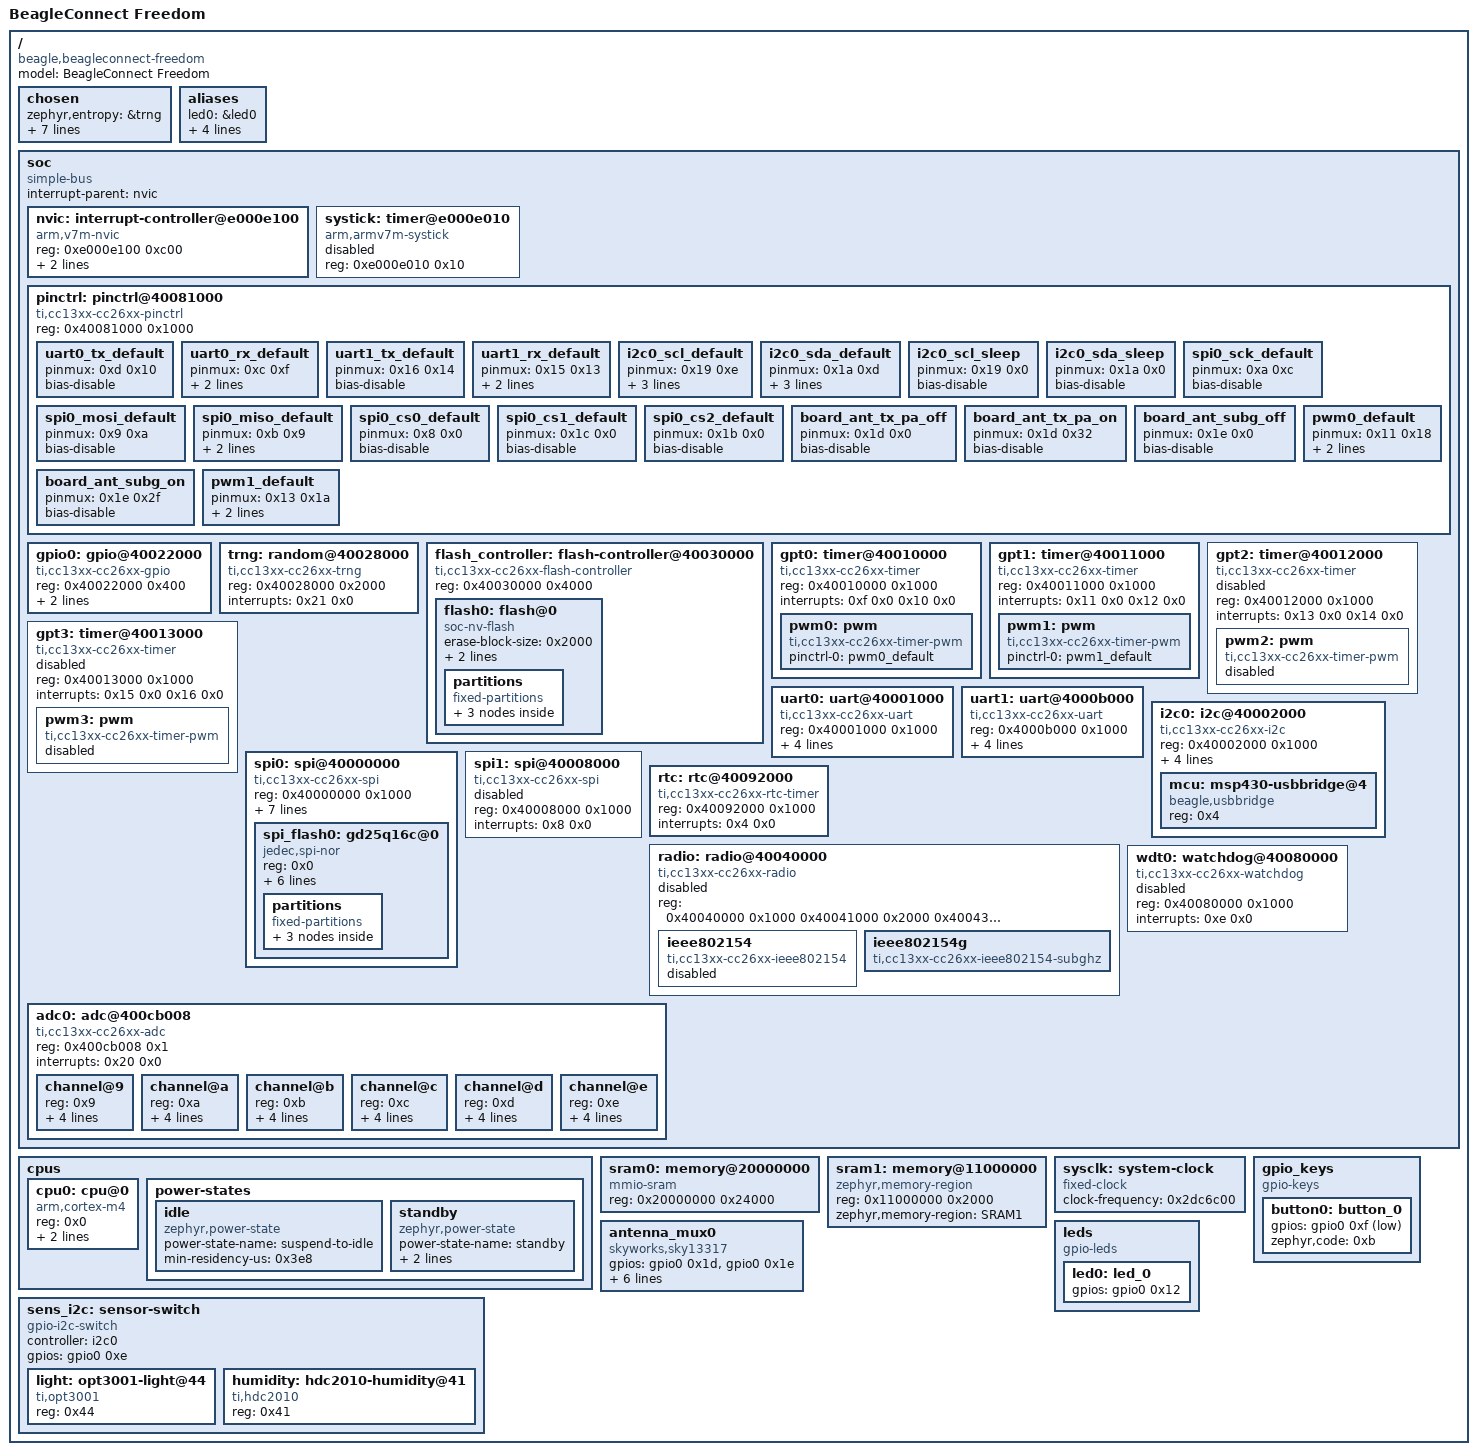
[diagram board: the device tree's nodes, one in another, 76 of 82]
/dts-v1/;

/ {
	#address-cells = < 0x1 >;
	#size-cells = < 0x1 >;
	model = "BeagleConnect Freedom";
	compatible = "beagle,beagleconnect-freedom";
	chosen {
		zephyr,entropy = &trng;
		zephyr,flash-controller = &flash_controller;
		zephyr,sram = &sram0;
		zephyr,console = &uart0;
		zephyr,shell-uart = &uart0;
		zephyr,flash = &flash0;
		zephyr,ieee802154 = &ieee802154g;
		zephyr,code-partition = &slot0_partition;
	};
	aliases {
		led0 = &led0;
		sw0 = &button0;
		mcuboot-button0 = &button0;
		sensor0 = &light;
		sensor1 = &humidity;
	};
	soc {
		#address-cells = < 0x1 >;
		#size-cells = < 0x1 >;
		compatible = "simple-bus";
		interrupt-parent = < &nvic >;
		ranges;
		nvic: interrupt-controller@e000e100 {
			#address-cells = < 0x1 >;
			compatible = "arm,v7m-nvic";
			reg = < 0xe000e100 0xc00 >;
			interrupt-controller;
			#interrupt-cells = < 0x2 >;
			arm,num-irq-priority-bits = < 0x3 >;
			phandle = < 0x1 >;
		};
		systick: timer@e000e010 {
			compatible = "arm,armv7m-systick";
			reg = < 0xe000e010 0x10 >;
			status = "disabled";
		};
		pinctrl: pinctrl@40081000 {
			compatible = "ti,cc13xx-cc26xx-pinctrl";
			reg = < 0x40081000 0x1000 >;
			uart0_tx_default: uart0_tx_default {
				pinmux = < 0xd 0x10 >;
				bias-disable;
				phandle = < 0x6 >;
			};
			uart0_rx_default: uart0_rx_default {
				pinmux = < 0xc 0xf >;
				bias-disable;
				input-enable;
				phandle = < 0x5 >;
			};
			uart1_tx_default: uart1_tx_default {
				pinmux = < 0x16 0x14 >;
				bias-disable;
				phandle = < 0x8 >;
			};
			uart1_rx_default: uart1_rx_default {
				pinmux = < 0x15 0x13 >;
				bias-disable;
				input-enable;
				phandle = < 0x7 >;
			};
			i2c0_scl_default: i2c0_scl_default {
				pinmux = < 0x19 0xe >;
				bias-pull-up;
				drive-open-drain;
				input-enable;
				phandle = < 0x9 >;
			};
			i2c0_sda_default: i2c0_sda_default {
				pinmux = < 0x1a 0xd >;
				bias-pull-up;
				drive-open-drain;
				input-enable;
				phandle = < 0xa >;
			};
			i2c0_scl_sleep: i2c0_scl_sleep {
				pinmux = < 0x19 0x0 >;
				bias-disable;
				phandle = < 0xb >;
			};
			i2c0_sda_sleep: i2c0_sda_sleep {
				pinmux = < 0x1a 0x0 >;
				bias-disable;
				phandle = < 0xc >;
			};
			spi0_sck_default: spi0_sck_default {
				pinmux = < 0xa 0xc >;
				bias-disable;
				phandle = < 0xd >;
			};
			spi0_mosi_default: spi0_mosi_default {
				pinmux = < 0x9 0xa >;
				bias-disable;
				phandle = < 0xe >;
			};
			spi0_miso_default: spi0_miso_default {
				pinmux = < 0xb 0x9 >;
				bias-disable;
				input-enable;
				phandle = < 0xf >;
			};
			spi0_cs0_default: spi0_cs0_default {
				pinmux = < 0x8 0x0 >;
				bias-disable;
				phandle = < 0x10 >;
			};
			spi0_cs1_default: spi0_cs1_default {
				pinmux = < 0x1c 0x0 >;
				bias-disable;
				phandle = < 0x11 >;
			};
			spi0_cs2_default: spi0_cs2_default {
				pinmux = < 0x1b 0x0 >;
				bias-disable;
				phandle = < 0x12 >;
			};
			board_ant_tx_pa_off: board_ant_tx_pa_off {
				pinmux = < 0x1d 0x0 >;
				bias-disable;
				phandle = < 0x16 >;
			};
			board_ant_tx_pa_on: board_ant_tx_pa_on {
				pinmux = < 0x1d 0x32 >;
				bias-disable;
				phandle = < 0x19 >;
			};
			board_ant_subg_off: board_ant_subg_off {
				pinmux = < 0x1e 0x0 >;
				bias-disable;
				phandle = < 0x17 >;
			};
			board_ant_subg_on: board_ant_subg_on {
				pinmux = < 0x1e 0x2f >;
				bias-disable;
				phandle = < 0x18 >;
			};
			pwm0_default: pwm0_default {
				pinmux = < 0x11 0x18 >;
				bias-disable;
				drive-strength = < 0x2 >;
				phandle = < 0x2 >;
			};
			pwm1_default: pwm1_default {
				pinmux = < 0x13 0x1a >;
				bias-disable;
				drive-strength = < 0x2 >;
				phandle = < 0x3 >;
			};
		};
		gpio0: gpio@40022000 {
			compatible = "ti,cc13xx-cc26xx-gpio";
			reg = < 0x40022000 0x400 >;
			interrupts = < 0x0 0x0 >;
			status = "okay";
			gpio-controller;
			#gpio-cells = < 0x2 >;
			phandle = < 0x13 >;
		};
		trng: random@40028000 {
			compatible = "ti,cc13xx-cc26xx-trng";
			reg = < 0x40028000 0x2000 >;
			interrupts = < 0x21 0x0 >;
			status = "okay";
		};
		flash_controller: flash-controller@40030000 {
			compatible = "ti,cc13xx-cc26xx-flash-controller";
			reg = < 0x40030000 0x4000 >;
			#address-cells = < 0x1 >;
			#size-cells = < 0x1 >;
			flash0: flash@0 {
				compatible = "soc-nv-flash";
				erase-block-size = < 0x2000 >;
				write-block-size = < 0x1 >;
				reg = < 0x0 0xb0000 >;
				partitions {
					compatible = "fixed-partitions";
					#address-cells = < 0x1 >;
					#size-cells = < 0x1 >;
					ti_ccfg_partition: partition@affa8 {
						compatible = "zephyr,memory-region";
						reg = < 0xaffa8 0x58 >;
						zephyr,memory-region = "FLASH_CCFG";
					};
					boot_partition: partition@0 {
						label = "mcuboot";
						reg = < 0x0 0x20000 >;
					};
					slot0_partition: partition@20000 {
						label = "image-0";
						reg = < 0x20000 0x8e000 >;
					};
				};
			};
		};
		gpt0: timer@40010000 {
			compatible = "ti,cc13xx-cc26xx-timer";
			reg = < 0x40010000 0x1000 >;
			interrupts = < 0xf 0x0 0x10 0x0 >;
			interrupt-names = "gpt0a", "gpt0b";
			status = "okay";
			pwm0: pwm {
				compatible = "ti,cc13xx-cc26xx-timer-pwm";
				#pwm-cells = < 0x3 >;
				status = "okay";
				pinctrl-0 = < &pwm0_default >;
				pinctrl-names = "default";
			};
		};
		gpt1: timer@40011000 {
			compatible = "ti,cc13xx-cc26xx-timer";
			reg = < 0x40011000 0x1000 >;
			interrupts = < 0x11 0x0 0x12 0x0 >;
			interrupt-names = "gpt1a", "gpt1b";
			status = "okay";
			pwm1: pwm {
				compatible = "ti,cc13xx-cc26xx-timer-pwm";
				#pwm-cells = < 0x3 >;
				status = "okay";
				pinctrl-0 = < &pwm1_default >;
				pinctrl-names = "default";
			};
		};
		gpt2: timer@40012000 {
			compatible = "ti,cc13xx-cc26xx-timer";
			reg = < 0x40012000 0x1000 >;
			interrupts = < 0x13 0x0 0x14 0x0 >;
			interrupt-names = "gpt2a", "gpt2b";
			status = "disabled";
			pwm2: pwm {
				compatible = "ti,cc13xx-cc26xx-timer-pwm";
				#pwm-cells = < 0x3 >;
				status = "disabled";
			};
		};
		gpt3: timer@40013000 {
			compatible = "ti,cc13xx-cc26xx-timer";
			reg = < 0x40013000 0x1000 >;
			interrupts = < 0x15 0x0 0x16 0x0 >;
			interrupt-names = "gpt3a", "gpt3b";
			status = "disabled";
			pwm3: pwm {
				compatible = "ti,cc13xx-cc26xx-timer-pwm";
				#pwm-cells = < 0x3 >;
				status = "disabled";
			};
		};
		uart0: uart@40001000 {
			compatible = "ti,cc13xx-cc26xx-uart";
			reg = < 0x40001000 0x1000 >;
			interrupts = < 0x5 0x0 >;
			clocks = < &sysclk >;
			status = "okay";
			current-speed = < 0x1c200 >;
			pinctrl-0 = < &uart0_rx_default &uart0_tx_default >;
			pinctrl-names = "default";
		};
		uart1: uart@4000b000 {
			compatible = "ti,cc13xx-cc26xx-uart";
			reg = < 0x4000b000 0x1000 >;
			interrupts = < 0x24 0x0 >;
			clocks = < &sysclk >;
			status = "okay";
			current-speed = < 0x1c200 >;
			pinctrl-0 = < &uart1_rx_default &uart1_tx_default >;
			pinctrl-names = "default";
		};
		i2c0: i2c@40002000 {
			compatible = "ti,cc13xx-cc26xx-i2c";
			#address-cells = < 0x1 >;
			#size-cells = < 0x0 >;
			reg = < 0x40002000 0x1000 >;
			interrupts = < 0x1 0x0 >;
			clock-frequency = < 0x61a80 >;
			status = "okay";
			pinctrl-0 = < &i2c0_scl_default &i2c0_sda_default >;
			pinctrl-1 = < &i2c0_scl_sleep &i2c0_sda_sleep >;
			pinctrl-names = "default", "sleep";
			phandle = < 0x1a >;
			mcu: msp430-usbbridge@4 {
				compatible = "beagle,usbbridge";
				reg = < 0x4 >;
			};
		};
		spi0: spi@40000000 {
			compatible = "ti,cc13xx-cc26xx-spi";
			#address-cells = < 0x1 >;
			#size-cells = < 0x0 >;
			reg = < 0x40000000 0x1000 >;
			interrupts = < 0x7 0x0 >;
			status = "okay";
			pinctrl-0 = < &spi0_sck_default &spi0_mosi_default &spi0_miso_default &spi0_cs0_default &spi0_cs1_default &spi0_cs2_default >;
			pinctrl-names = "default";
			cs-gpios = < &gpio0 0x8 0x1 >, < &gpio0 0x1c 0x1 >, < &gpio0 0x1b 0x1 >;
			spi_flash0: gd25q16c@0 {
				compatible = "jedec,spi-nor";
				reg = < 0x0 >;
				spi-max-frequency = < 0x1e8480 >;
				size = < 0x200000 >;
				has-dpd;
				t-enter-dpd = < 0x4e20 >;
				t-exit-dpd = < 0x186a0 >;
				jedec-id = [ C8 40 15 ];
				partitions {
					compatible = "fixed-partitions";
					#address-cells = < 0x1 >;
					#size-cells = < 0x1 >;
					slot1_partition: partition@0 {
						label = "image-1";
						reg = < 0x0 0x8e000 >;
					};
					scratch_partition: partition@8e000 {
						label = "image-scratch";
						reg = < 0x8e000 0x20000 >;
					};
					storage_partition: partition@ae000 {
						label = "storage";
						reg = < 0xae000 0x100000 >;
					};
				};
			};
		};
		spi1: spi@40008000 {
			compatible = "ti,cc13xx-cc26xx-spi";
			#address-cells = < 0x1 >;
			#size-cells = < 0x0 >;
			reg = < 0x40008000 0x1000 >;
			interrupts = < 0x8 0x0 >;
			status = "disabled";
		};
		rtc: rtc@40092000 {
			compatible = "ti,cc13xx-cc26xx-rtc-timer";
			reg = < 0x40092000 0x1000 >;
			interrupts = < 0x4 0x0 >;
			status = "okay";
		};
		radio: radio@40040000 {
			compatible = "ti,cc13xx-cc26xx-radio";
			status = "disabled";
			reg = < 0x40040000 0x1000 0x40041000 0x2000 0x40043000 0x1000 0x40044000 0x1000 >;
			reg-names = "RFC_PWR", "RFC_DBELL", "RFC_RAT", "RFC_FSCA";
			ieee802154: ieee802154 {
				compatible = "ti,cc13xx-cc26xx-ieee802154";
				status = "disabled";
			};
			ieee802154g: ieee802154g {
				compatible = "ti,cc13xx-cc26xx-ieee802154-subghz";
				status = "okay";
			};
		};
		wdt0: watchdog@40080000 {
			compatible = "ti,cc13xx-cc26xx-watchdog";
			reg = < 0x40080000 0x1000 >;
			interrupts = < 0xe 0x0 >;
			status = "disabled";
		};
		adc0: adc@400cb008 {
			compatible = "ti,cc13xx-cc26xx-adc";
			reg = < 0x400cb008 0x1 >;
			interrupts = < 0x20 0x0 >;
			status = "okay";
			#io-channel-cells = < 0x1 >;
			#address-cells = < 0x1 >;
			#size-cells = < 0x0 >;
			channel@9 {
				reg = < 0x9 >;
				zephyr,gain = "ADC_GAIN_1";
				zephyr,reference = "ADC_REF_INTERNAL";
				zephyr,acquisition-time = < 0x0 >;
				zephyr,resolution = < 0xc >;
			};
			channel@a {
				reg = < 0xa >;
				zephyr,gain = "ADC_GAIN_1";
				zephyr,reference = "ADC_REF_INTERNAL";
				zephyr,acquisition-time = < 0x0 >;
				zephyr,resolution = < 0xc >;
			};
			channel@b {
				reg = < 0xb >;
				zephyr,gain = "ADC_GAIN_1";
				zephyr,reference = "ADC_REF_INTERNAL";
				zephyr,acquisition-time = < 0x0 >;
				zephyr,resolution = < 0xc >;
			};
			channel@c {
				reg = < 0xc >;
				zephyr,gain = "ADC_GAIN_1";
				zephyr,reference = "ADC_REF_INTERNAL";
				zephyr,acquisition-time = < 0x0 >;
				zephyr,resolution = < 0xc >;
			};
			channel@d {
				reg = < 0xd >;
				zephyr,gain = "ADC_GAIN_1";
				zephyr,reference = "ADC_REF_INTERNAL";
				zephyr,acquisition-time = < 0x0 >;
				zephyr,resolution = < 0xc >;
			};
			channel@e {
				reg = < 0xe >;
				zephyr,gain = "ADC_GAIN_1";
				zephyr,reference = "ADC_REF_INTERNAL";
				zephyr,acquisition-time = < 0x0 >;
				zephyr,resolution = < 0xc >;
			};
		};
	};
	cpus {
		#address-cells = < 0x1 >;
		#size-cells = < 0x0 >;
		cpu0: cpu@0 {
			device_type = "cpu";
			compatible = "arm,cortex-m4";
			reg = < 0x0 >;
			cpu-power-states = < &idle &standby >;
			clock-frequency = < 0x2dc6c00 >;
		};
		power-states {
			idle: idle {
				compatible = "zephyr,power-state";
				power-state-name = "suspend-to-idle";
				min-residency-us = < 0x3e8 >;
				phandle = < 0x14 >;
			};
			standby: standby {
				compatible = "zephyr,power-state";
				power-state-name = "standby";
				min-residency-us = < 0x1388 >;
				exit-latency-us = < 0xf0 >;
				phandle = < 0x15 >;
			};
		};
	};
	sram0: memory@20000000 {
		compatible = "mmio-sram";
		reg = < 0x20000000 0x24000 >;
	};
	sram1: memory@11000000 {
		compatible = "zephyr,memory-region", "mmio-sram";
		reg = < 0x11000000 0x2000 >;
		zephyr,memory-region = "SRAM1";
	};
	sysclk: system-clock {
		compatible = "fixed-clock";
		clock-frequency = < 0x2dc6c00 >;
		#clock-cells = < 0x0 >;
		phandle = < 0x4 >;
	};
	gpio_keys {
		compatible = "gpio-keys";
		button0: button_0 {
			gpios = < &gpio0 0xf 0x1 >;
			zephyr,code = < 0xb >;
		};
	};
	antenna_mux0: antenna_mux0 {
		compatible = "skyworks,sky13317";
		status = "okay";
		gpios = < &gpio0 0x1d 0x0 >, < &gpio0 0x1e 0x0 >;
		pinctrl-0 = < &board_ant_tx_pa_off &board_ant_subg_off >;
		pinctrl-1 = < &board_ant_tx_pa_off &board_ant_subg_on >;
		pinctrl-2 = < &board_ant_tx_pa_on &board_ant_subg_on >;
		pinctrl-names = "default", "ant_subg", "ant_subg_pa";
	};
	leds: leds {
		compatible = "gpio-leds";
		led0: led_0 {
			gpios = < &gpio0 0x12 0x0 >;
		};
	};
	sens_i2c: sensor-switch {
		status = "okay";
		compatible = "gpio-i2c-switch";
		#address-cells = < 0x1 >;
		#size-cells = < 0x0 >;
		controller = < &i2c0 >;
		gpios = < &gpio0 0xe 0x0 >;
		light: opt3001-light@44 {
			status = "okay";
			compatible = "ti,opt3001";
			reg = < 0x44 >;
		};
		humidity: hdc2010-humidity@41 {
			status = "okay";
			compatible = "ti,hdc2010";
			reg = < 0x41 >;
		};
	};
};
